# GD32VW553x register map
File version: 1.0
GD32VW553x RISC-V Microcontroller based device
CPU: other RISC-V, little endian, no MPU, FPU
Registers are 32-bit, read-write, reset 0x0 unless marked. A register's access mark holds for its fields unless they carry their own. Offsets are from the block's base; lines under a group give offsets from that group; [hi:lo] are bit positions; {n}, {i} and the like mark numbered series; 'fields as' and 'values as' point back to an identical list; <NAME> marks a mode.

## Memory map
0x40000000 TIMER1 size 0x400 — General-level0-timer
0x40000400 TIMER2 size 0x400 — General-purpose-timers
0x40001000 TIMER5 size 0x400 — Basic-timers
0x40002800 RTC size 0x400 — Real time clock
0x40002C00 WWDGT size 0x400 — Window watchdog timer
0x40003000 FWDGT size 0x400 — free watchdog timer
0x40004400 UART1 size 0x400 — Universal asynchronous receiver /transmitter
0x40004800 USART0 size 0x400 — Universal synchronous/asynchronous receiver /transmitter
0x40005400 I2C0 size 0x400 — Inter-integrated circuit interface
0x40005800 I2C1 size 0x400
0x40007000 PMU size 0x400 — Power management unit
0x40010000 TIMER0 size 0x400 — Advanced-timers
0x40011000 UART2 size 0x400
0x40012000 ADC size 0x400 — Analog to digital converter
0x40013000 SPI size 0x400 — Serial peripheral interface
0x40013800 SYSCFG size 0x400 — System configuration registers
0x40013C00 EXTI size 0x400 — External interrupt/event controller
0x40018000 TIMER15 size 0x400 — General-purpose-timers
0x40018400 TIMER16 size 0x400 — General-purpose-timers
0x40020000 GPIOA size 0x400 — General-purpose I/Os
0x40020400 GPIOB size 0x400
0x40020800 GPIOC size 0x400
0x40022000 FMC size 0x400 — Flash memory controller
0x40022800 EFUSE size 0x400 — Electronic fuse
0x40023000 CRC size 0x400 — Cyclic redundancy checks management unit
0x40023800 RCU size 0x400 — Reset and clock unit
0x40025800 QSPI size 0x400 — Quad-SPI interface
0x40026000 DMA size 0x400 — DMA controller
0x4C060000 CAU size 0x400 — Cryptographic Acceleration Unit
0x4C060400 HAU size 0x400 — Hash Acceleration Unit
0x4C060800 TRNG size 0x400 — True random number generator
0x4C061000 PKCAU size 0x400 — Public Key Cryptographic Acceleration Unit
0xD1000000 CPU_TIMER size 0xFFFF
0xD2000000 ECLIC size 0xFFFF — Enhanced Core Local Interrupt Controller
0xE0044000 DBG size 0x400 — Debug

## Interrupts
7 CLIC_INT_TMR (CPU_TIMER)
19 WWDGT
20 LVD (EXTI)
21 RTC_Tamper_TimeStamp (RTC)
22 RTC_WKUP (RTC)
23 FMC
24 RCU
25 EXTI_Line0 (EXTI)
26 EXTI_Line1 (EXTI)
27 EXTI_Line2 (EXTI)
28 EXTI_Line3 (EXTI)
29 EXTI_Line4 (EXTI)
{n+30} DMA_Channel{n} (DMA) (n=0..7)
38 ADC
42 EXTI_line9_5 (EXTI)
43 TIMER0_BRK (TIMER0)
44 TIMER0_UP (TIMER0)
45 TIMER0COM (TIMER0)
46 TIMER0_CC (TIMER0)
47 TIMER1
48 TIMER2
50 I2C0_EV (I2C0)
51 I2C0_ER (I2C0)
52 I2C1_EV (I2C1)
53 I2C1_ER (I2C1)
54 SPI
56 USART0
57 UART1
58 UART2
59 EXTI_line15_10 (EXTI)
60 RTC_Alarm (RTC)
63 TIMER15
64 TIMER16
70 I2C0_WK (I2C0)
71 USART0_WK (USART0)
73 TIMER5
84 WIFI_Wakeup (EXTI)
85 BLE_Wakeup (EXTI)
86 PLF_Wakeup (EXTI)
95 PMU
98 CAU
99 HAU_TRNG (HAU, TRNG)
113 EFUSE
114 QSPI
115 PKCAU

## ADC — Analog to digital converter
Base 0x40012000
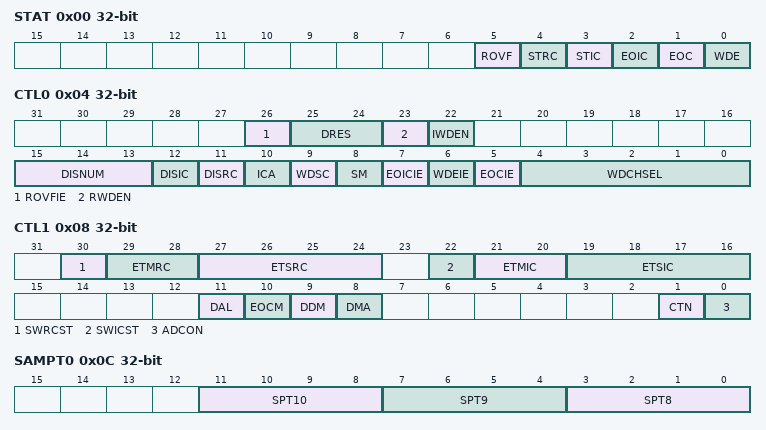
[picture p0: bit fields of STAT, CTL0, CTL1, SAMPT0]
0x00 STAT — status register
  [5] ROVF — Regular data register overflow
  [4] STRC — Start flag of regular channel group
  [3] STIC — Start flag of inserted channel group
  [2] EOIC — End of inserted group conversion flag
  [1] EOC — End of group conversion flag
  [0] WDE — Analog watchdog event flag
0x04 CTL0 — Control register 0
  [26] ROVFIE — Interrupt enable for ROVF
  [25:24] DRES — ADC data resolution
  [23] RWDEN — Regular channel analog watchdog enable
  [22] IWDEN — Inserted channel analog watchdog enable
  [15:13] DISNUM — Number of conversions in discontinuous mode
  [12] DISIC — Discontinuous mode on inserted channels
  [11] DISRC — Discontinuous mode on regular channels
  [10] ICA — Inserted channel group convert automatically
  [9] WDSC — When in scan mode, analog watchdog is effective on a single channel
  [8] SM — Scan mode
  [7] EOICIE — Interrupt enable for EOIC
  [6] WDEIE — Interrupt enable for WDE
  [5] EOCIE — Interrupt enable for EOC
  [4:0] WDCHSEL — Analog watchdog channel select
0x08 CTL1 — Control register 1
  [30] SWRCST — Software start on regular channel
  [29:28] ETMRC — External trigger mode for regular channel
  [27:24] ETSRC — External trigger select for regular channel
  [22] SWICST — Software start on inserted channel
  [21:20] ETMIC — External trigger mode for inserted channel
  [19:16] ETSIC — External trigger select for inserted channel
  [11] DAL — Data alignment
  [10] EOCM — End of conversion mode
  [9] DDM — DMA disable mode
  [8] DMA — DMA request enable for regular channel
  [1] CTN — Continuous mode
  [0] ADCON
0x0C SAMPT0 — Sample time register 0
  [11:8] SPT10 — refer to SPT8[3:0] description
  [7:4] SPT9 — refer to SPT8[3:0] description
  [3:0] SPT8 — Channel sample time
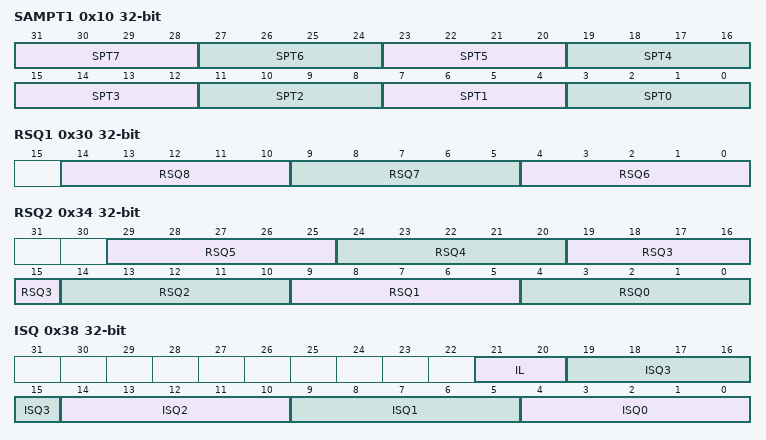
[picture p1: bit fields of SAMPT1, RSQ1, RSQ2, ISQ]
0x10 SAMPT1 — Sample time register 1
  [4n+3:4n] SPT{n} (n=1..7) — Refer to SPT0[3:0] description
  [3:0] SPT0 — Channel sample time
{0x14+4i} IOFF{i} (i=0..3) — Inserted channel data offset register {i}
  [11:0] IOFF — Data offset for inserted channel x
0x24 WDHT reset 0xFFF — Watchdog high threshold register
  [11:0] WDHT — High threshold for analog watchdog
0x28 WDLT — Watchdog low threshold register
  [11:0] WDLT — Low threshold for analog watchdog
0x2C RSQ0 — Regular sequence register 0
  [23:20] RL — Regular channel group length
0x30 RSQ1 — Regular sequence register 1
  [14:10] RSQ8 — Refer to RSQ0[4:0] description
  [9:5] RSQ7 — Refer to RSQ0[4:0] description
  [4:0] RSQ6 — Refer to RSQ0[4:0] description
0x34 RSQ2 — Regular sequence register 2
  [5n+4:5n] RSQ{n} (n=1..5) — Refer to RSQ0[4:0] description
  [4:0] RSQ0 — The channel number (0
0x38 ISQ — Inserted sequence register
  [21:20] IL — Inserted channel group length
  [19:15] ISQ3 — Refer to ISQ0[4:0] description
  [14:10] ISQ2 — Refer to ISQ0[4:0] description
  [9:5] ISQ1 — Refer to ISQ0[4:0] description
  [4:0] ISQ0 — The channel number (0
{0x3C+4i} IDATA{i} ro (i=0..3) — Inserted data register {i}
  [15:0] IDATAn — Inserted number n conversion data
0x4C RDATA ro — Regular data register
  [15:0] RDATA — Regular channel data
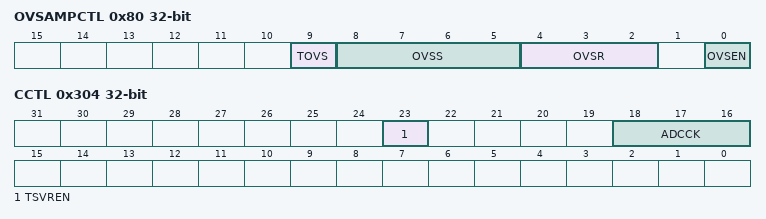
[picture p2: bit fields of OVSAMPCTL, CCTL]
0x80 OVSAMPCTL — Oversampling control register
  [9] TOVS — Triggered Oversampling
  [8:5] OVSS — Oversampling shift
  [4:2] OVSR — Oversampling ratio
  [0] OVSEN — Oversampling enable
0x304 CCTL — Commom control register
  [23] TSVREN — Channel 9 (temperature sensor) and 10 (internal reference voltage) enable of ADC
  [18:16] ADCCK — ADC clock
